# GD32H77x_78x register map
File version: 1.0
CPU: CM7 r1p2, little endian, MPU, FPU, 4 interrupt priority bits
Registers are 32-bit, read-write, reset 0x0 unless marked. A register's access mark holds for its fields unless they carry their own. Offsets are from the block's base; [hi:lo] are bit positions; {n}, {i} and the like mark numbered series.

## NVMC — Non-volatile memory controller
Base 0x52002000
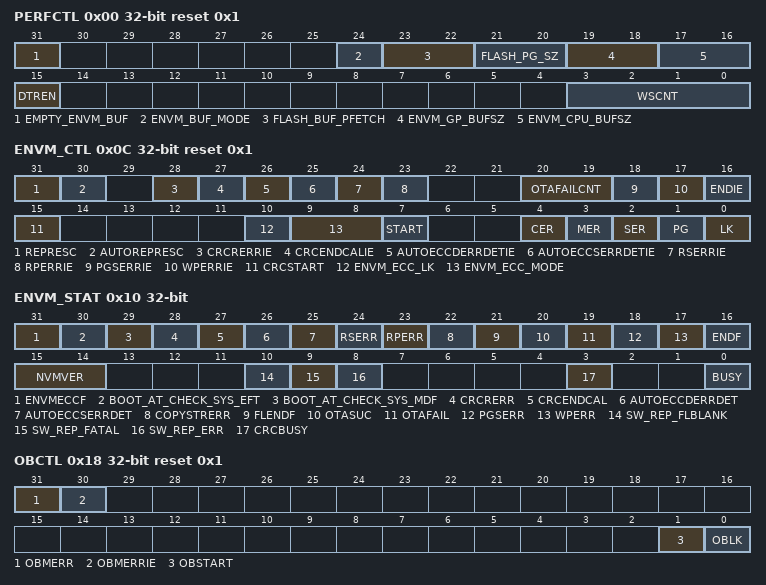
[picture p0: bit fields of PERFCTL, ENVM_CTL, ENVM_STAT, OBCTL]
0x00 PERFCTL access per field reset 0x1 — NVM performance control register
  [31] EMPTY_ENVM_BUF wo — Empty eNVM buffer (general buffer and CPU buffer) function, takes effect when buffer is idle.
  [24] ENVM_BUF_MODE rw — ENVM buffer mode
  [23:22] FLASH_BUF_PFETCH rw — Flash buffer prefetch control.
  [21:20] FLASH_PG_SZ rw — Flash program size.
  [19:18] ENVM_GP_BUFSZ rw — ENVM general purpose buffer size (for masters except CPU).
  [17:16] ENVM_CPU_BUFSZ rw — ENVM CPU buffer size
  [15] DTREN rw — Flash DTR (Double Transfer Rate) mode enable. (Not for case4)
  [3:0] WSCNT rw — Wait state counter register
0x04 ENVM_KEY wo — ENVM unlock key register
  [31:0] KEY — NVMC_ENVM_CTL unlock register
0x08 OBKEY wo — Option byte unlock key register
  [31:0] OBKEY — These bits are only be written by software.
0x0C ENVM_CTL access per field reset 0x1 — ENVM control register
  [31] REPRESC wo — Clear the result of the self-repair function, including the counter, error address, and status. (Including ROBBCNT, ERR2CNT, ERR1CNT, FLBLANK bit in NVMC_ENVM_REPCS register, NVMC_ENVM_ROBBADDRx, NVMC_ENVM_UNREPECCADDRx). The repair function refers to the self-check repair function after the reset.
  [30] AUTOREPRESC wo — Clear the result of the automatic repair function, including the counter, error address, and status. (Including AUTOECCSERRDET, AUTOECCDERRDET bit in NVMC_ENVM_STAT register, NMIERRINT, FLBLANK, ECC1CNTIF, ECC2CNTIF, REPERRSTAT bit in NVMC_ENVM_REPCS register, NVMC_ENVM_AUTOERR1ADDRx, NVMC_ENVM_AUTOERR2ADDRx, NVMC_NMIERRADDR). The automatic repair function refers to the automatic repair function in the process of bus reading eNVM.
  [28] CRCRERRIE rw — ENVM CRC read error interrupt enable
  [27] CRCENDCALIE rw — ENVM CRC end of calculation interrupt enable
  [26] AUTOECCDERRDETIE rw — ENVM ECC two bit errors detect interrupt enable.
  [25] AUTOECCSERRDETIE rw — ENVM ECC one bit error detect interrupt enable.
  [24] RSERRIE rw — Read secure error interrupt enable.
  [23] RPERRIE rw — Read protection error interrupt enable
  [20:19] OTAFAILCNT rw — OTA fail times count, this bit resets upon power-on reset, but is unaffected by system reset.
  [18] PGSERRIE rw — Program sequence error interrupt enable
  [17] WPERRIE rw — Erase / program protection error interrupt enable
  [16] ENDIE rw — End of operation interrupt enable
  [15] CRCSTART rw — CRC check is enabled to check the eNVM content between the NVMC_OBREPSTADDR_MDF and the NVMC_OBREPENDADDR_MDF. When the end or error occurs, this bit is cleared by hardware.
  [10] ENVM_ECC_LK rw — ENVM_ECC_LK, which can only write 1. After writing 1, ENVM_ECC_MODE cannot be overwritten. The ENVM_ECC_MODE is used to test related functions. After the test is complete, users are advised to enable and lock the ENVM_ECC_LK function.
  [9:8] ENVM_ECC_MODE rw — ENVM ECC mode configuration bit
  [7] START rw — Send erase command to NVMC
  [4] CER rw — Chip erase command bit
  [3] MER rw — ENVM mass erase command bit (Not for case4)
  [2] SER rw — ENVM sector erase command bit
  [1] PG rw — ENVM program command bit
  [0] LK rw — NVMC_ENVM_CTL lock bit
0x10 ENVM_STAT access per field — ENVM status register
  [31] ENVMECCF ro — ENVM ECC function flag.
  [30] BOOT_AT_CHECK_SYS_EFT ro — Flag generated by the option byte EFT, indicating boot from the check_bootLoader (Not for case4)
  [29] BOOT_AT_CHECK_SYS_MDF ro — Flag generated by the option byte MDF, indicating boot from the check_bootLoader. This bit contains only the FW_UPDATE and software self-check settings. (Not for case4)
  [28] CRCRERR rw — CRC read error flag
  [27] CRCENDCAL rw — CRC end of calculation flag
  [26] AUTOECCDERRDET ro — Two bit errors detect flag bit.
  [25] AUTOECCSERRDET ro — One bit error detect flag bit.
  [24] RSERR rw — Read secure error flag bit.
  [23] RPERR rw — Read protection error flag bit.
  [22] COPYSTRERR rw — Copy startup failure error flag bit.
  [21] FLENDF rw — End of flash operation flag bit. (Not for case4)
  [20] OTASUC rw — OTA upgrade, check_bootloader check success flag. (Not for case4)
  [19] OTAFAIL rw — OTA upgrade, check_bootloader check failure flag. (Not for case4)
  [18] PGSERR rw — Program sequence error flag bit.
  [17] WPERR rw — Erase / program protection error flag bit.
  [16] ENDF rw — End of operation flag bit.
  [15:14] NVMVER ro — Nvm version
  [10] SW_REP_FLBLANK rw — Software self-check repair flash backup content blank flag (Not for case4)
  [9] SW_REP_FATAL rw — Software self-check repair fatal error flag (Not for case4)
  [8] SW_REP_ERR rw — Software self-check repair error flag (Not for case4)
  [3] CRCBUSY ro — ENVM CRC busy flag bit
  [0] BUSY ro — The eNVM is busy bit
0x14 ENVM_ADDR — ENVM address register
  [31:0] ADDR — ENVM erase command address bits
0x18 OBCTL reset 0x1 — Option byte control register
  [31] OBMERR — Option byte modify error flag.
  [30] OBMERRIE — Option byte modify error interrupt enable.
  [1] OBSTART — Send option byte change command to NVMC bit.
  [0] OBLK — NVMC_OBCTL lock bit
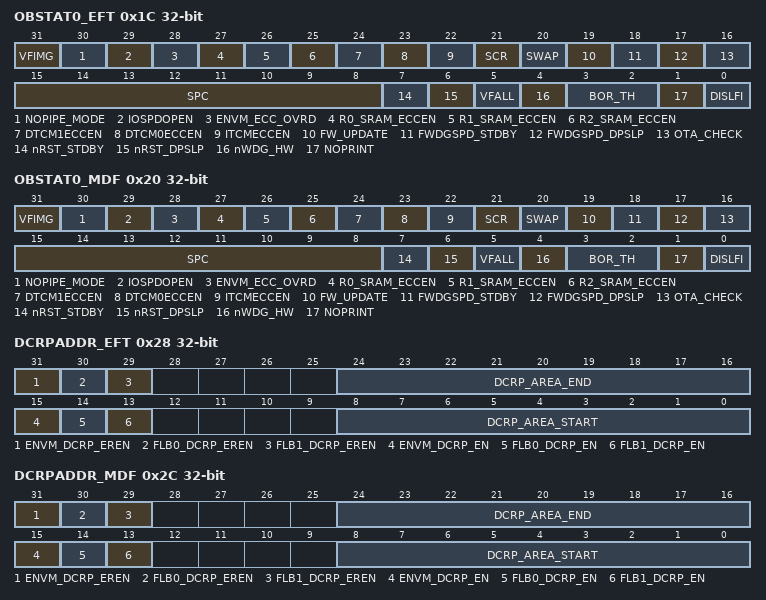
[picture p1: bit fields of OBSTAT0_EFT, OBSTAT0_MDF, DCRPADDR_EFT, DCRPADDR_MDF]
0x1C OBSTAT0_EFT ro — Option byte status register 0
  [31] VFIMG — Firmware image verification enable bit
  [30] NOPIPE_MODE — Pipeline mode
  [29] IOSPDOPEN — Allowed enable status bit for I/O speed optimization at low-voltage.
  [28] ENVM_ECC_OVRD — ENVM ECC override enable status bit
  [27] R0_SRAM_ECCEN — Region 0 SRAM ECC enable status bit
  [26] R1_SRAM_ECCEN — Region 1 SRAM ECC enable status bit
  [25] R2_SRAM_ECCEN — Region 2 SRAM ECC enable status bit
  [24] DTCM1ECCEN — DTCM1 ECC function enable status bit
  [23] DTCM0ECCEN — DTCM0 ECC function enable status bit
  [22] ITCMECCEN — ITCM ECC function enable status bit
  [21] SCR — Secure mode status bit
  [20] SWAP — SWAP status bit (Not for case2 and case4)
  [19] FW_UPDATE — Firmware update status bit (Not for case4)
  [18] FWDGSPD_STDBY — FWDGT suspend option in standby mode status bit
  [17] FWDGSPD_DPSLP — FWDGT suspend option in deepsleep mode status bit
  [16] OTA_CHECK — OTA check status bit (Not for case4)
  [15:8] SPC — Security protection level option byte status bits
  [7] nRST_STDBY — Option byte standby reset status bit
  [6] nRST_DPSLP — Option byte deepsleep reset status bit
  [5] VFALL — Firmware image (image must contain a certificate) verification enable bit
  [4] nWDG_HW — Watchdog status bit
  [3:2] BOR_TH — BOR threshold status bits
  [1] NOPRINT — No information is printed during secure boot
  [0] DISLFI — Licensed firmware install ( LFI ) disable
0x20 OBSTAT0_MDF — Option byte status register 0
  [31] VFIMG — Firmware image verification enable bit
  [30] NOPIPE_MODE — Pipeline mode
  [29] IOSPDOPEN — Allowed enable configuration bit for I/O speed optimization at low-voltage.
  [28] ENVM_ECC_OVRD — ENVM ECC override enable configuration bit
  [27] R0_SRAM_ECCEN — Region 0 SRAM ECC enable configuration bit
  [26] R1_SRAM_ECCEN — Region 1 SRAM ECC enable configuration bit
  [25] R2_SRAM_ECCEN — Region 2 SRAM ECC enable configuration bit
  [24] DTCM1ECCEN — DTCM1 ECC function enable configuration bit
  [23] DTCM0ECCEN — DTCM0 ECC function enable configuration bit
  [22] ITCMECCEN — ITCM ECC function enable configuration bit
  [21] SCR — Secure mode configuration bit
  [20] SWAP — SWAP configuration bit (Not for case2 and case4)
  [19] FW_UPDATE — Firmware update configuration bit (Not for case4)
  [18] FWDGSPD_STDBY — FWDGT suspend option in standby mode configuration bit
  [17] FWDGSPD_DPSLP — FWDGT suspend option in deepsleep mode configuration bit
  [16] OTA_CHECK — OTA check configuration bits (Not for case4)
  [15:8] SPC — Security protection level option configuration bits
  [7] nRST_STDBY — Option byte standby reset configuration bit
  [6] nRST_DPSLP — Option byte deepsleep reset configuration bit
  [5] VFALL — Firmware image (image must contain a certificate) verification configuration bit
  [4] nWDG_HW — Watchdog configuration bit
  [3:2] BOR_TH — BOR threshold configuration bits
  [1] NOPRINT — No information is printed during secure boot
  [0] DISLFI — Licensed firmware install ( LFI ) disable
0x28 DCRPADDR_EFT ro — DCRP address register
  [31] ENVM_DCRP_EREN — ENVM DCRP area erase enable status bit.
  [30] FLB0_DCRP_EREN — Flash bank0 DCRP area erase enable status bit.
  [29] FLB1_DCRP_EREN — Flash bank1 DCRP area erase enable status bit.
  [24:16] DCRP_AREA_END — DCRP area end address status bits
  [15] ENVM_DCRP_EN — ENVM region DCRP function enable status bits
  [14] FLB0_DCRP_EN — Flash bank0 region DCRP function enable status bits
  [13] FLB1_DCRP_EN — Flash bank1 region DCRP function enable status bits
  [8:0] DCRP_AREA_START — DCRP area start address status bits
0x2C DCRPADDR_MDF — DCRP address register
  [31] ENVM_DCRP_EREN — ENVM DCRP area erase enable configuration bit. (Case4: This bit defaults to 1 and cannot be modified)
  [30] FLB0_DCRP_EREN — Flash bank0 DCRP area erase enable configuration bit. (Not for case4)
  [29] FLB1_DCRP_EREN — Flash bank1 DCRP area erase enable configuration bit. (Not for case4)
  [24:16] DCRP_AREA_END — DCRP area end address configuration bits
  [15] ENVM_DCRP_EN — ENVM region DCRP function enable configuration bits (Case4: This bit defaults to 1 and cannot be modified)
  [14] FLB0_DCRP_EN — Flash bank0 region DCRP function enable configuration bits (Not for case4)
  [13] FLB1_DCRP_EN — Flash bank1 region DCRP function enable configuration bits (Not for case4)
  [8:0] DCRP_AREA_START — DCRP area start address configuration bits
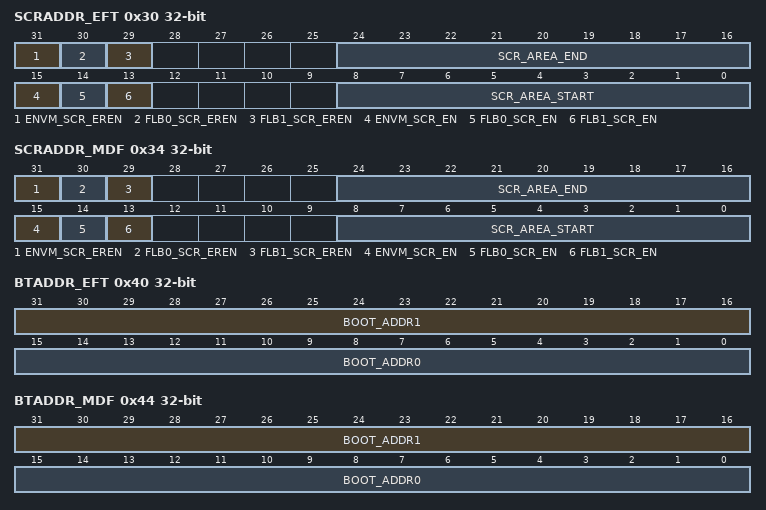
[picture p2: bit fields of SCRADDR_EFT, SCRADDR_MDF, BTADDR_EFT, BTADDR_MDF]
0x30 SCRADDR_EFT ro — Secure address register
  [31] ENVM_SCR_EREN — ENVM secure user area erase enable option status bit.
  [30] FLB0_SCR_EREN — Flash bank0 secure user area erase enable option status bit.
  [29] FLB1_SCR_EREN — Flash bank1 secure user area erase enable option status bit.
  [24:16] SCR_AREA_END — Secure user area end address status bits
  [15] ENVM_SCR_EN — ENVM region SCR function enable status bits
  [14] FLB0_SCR_EN — Flash bank0 region SCR function enable status bits
  [13] FLB1_SCR_EN — Flash bank1 region SCR function enable status bits
  [8:0] SCR_AREA_START — Secure user area start address status bits
0x34 SCRADDR_MDF — Secure address register
  [31] ENVM_SCR_EREN — ENVM secure user area erase enable option configuration bit. (Case4: This bit defaults to 1 and cannot be modified)
  [30] FLB0_SCR_EREN — Flash bank0 secure user area erase enable option configuration bit. (Not for case4)
  [29] FLB1_SCR_EREN — Flash bank1 secure user area erase enable option configuration bit. (Not for case4)
  [24:16] SCR_AREA_END — Secure user area end address configuration bits
  [15] ENVM_SCR_EN — ENVM region SCR function enable configuration bits (Case4: This bit defaults to 1 and cannot be modified)
  [14] FLB0_SCR_EN — Flash bank0 region SCR function enable configuration bits (Not for case4)
  [13] FLB1_SCR_EN — Flash bank1 region SCR function enable configuration bits (Not for case4)
  [8:0] SCR_AREA_START — Secure user area start address configuration bits
0x38 WP_ENVM_EFT ro reset 0xFFFF — NVMC erase / program protection register of ENVM
  [15:0] WP — ENVM sector erase / program protection option status bit
0x3C WP_ENVM_MDF — NVMC erase / program protection register of ENVM
  [15:0] WP — ENVM sector erase / program protection option configuration bit
0x40 BTADDR_EFT ro — Boot address register
  [31:16] BOOT_ADDR1 — Boot address 1 status bits
  [15:0] BOOT_ADDR0 — Boot address 0 status bits
0x44 BTADDR_MDF — Boot address register
  [31:16] BOOT_ADDR1 — Boot address 1 configuration bits.
  [15:0] BOOT_ADDR0 — Boot address 0 configuration bits.
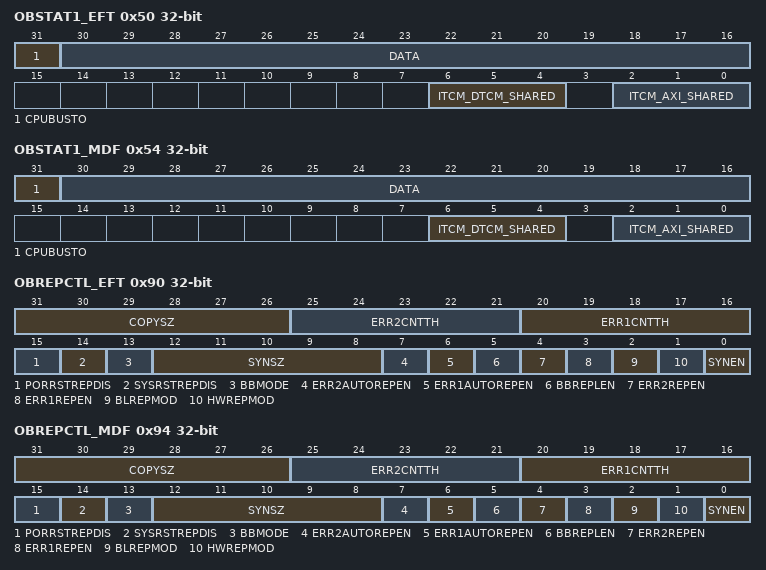
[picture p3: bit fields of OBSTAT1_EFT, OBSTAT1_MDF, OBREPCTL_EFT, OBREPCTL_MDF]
0x50 OBSTAT1_EFT ro — Option byte status register 1
  [31] CPUBUSTO — CPU bus timeout enable bit.
  [30:16] DATA — User defined option byte data status value
  [6:4] ITCM_DTCM_SHARED — ITCM and DTCM RAM sharing status bit
  [2:0] ITCM_AXI_SHARED — ITCM and AXI RAM sharing status bit
0x54 OBSTAT1_MDF — Option byte status register 1
  [31] CPUBUSTO — CPU bus timeout enable bit.
  [30:16] DATA — User defined option byte data configuration value
  [6:4] ITCM_DTCM_SHARED — ITCM and DTCM RAM sharing configuration configure bit.
  [2:0] ITCM_AXI_SHARED — ITCM and AXI RAM sharing configuration bits.
0x5C ENVM_CRCRESULT ro
  [31:0] CRC_RESULT — CRC calculation result, if CRCRERR is set 1, the value of CRC_RESULT[31:0] is 0x0000 0000.
0x60 ENVM_SW_REP_FATAL_ADDR ro — ENVM software repair fatal address register
  [31:0] SW_REP_FATAL_ADDR — The first blank address of the flash backup area or fatal address detected by software self-check. The address is in eNVM address area.
0x80 WP0_FLASH_EFT ro — NVMC erase / program protection register 0 of flash
  [31:0] WP — Flash sector erase / program protection option status bit
0x84 WP1_FLASH_EFT ro — NVMC erase / program protection register 1 of flash
  [27:0] WP — Flash sector erase / program protection option status bit
0x88 WP0_FLASH_MDF — NVMC erase / program protection register 0 of flash
  [31:0] WP — Flash sector erase / program protection option configuration bits.
0x8C WP1_FLASH_MDF — NVMC erase / program protection register 1 of flash
  [27:0] WP — Flash sector erase / program protection option configuration bits.
0x90 OBREPCTL_EFT ro — Option byte repair control register
  [31:26] COPYSZ — Copy size during OTA upgrade, the granularity is 32KB, that is, when 6'h3F is set, 2MB of space is copy zone.
  [25:21] ERR2CNTTH — Two bit error counter threshold status bit
  [20:16] ERR1CNTTH — One bit error counter threshold status bit
  [15] PORRSTREPDIS — The power-on reset self-check repair function enable status bit
  [14] SYSRSTREPDIS — The system reset self-check repair function enable status bit
  [13] BBMODE — Mode of determining whether the repair is successful after the repair.
  [12:8] SYNSZ — Synchronize size status bit
  [7] ERR2AUTOREPEN — 2 bit error automatic repair enable status bit
  [6] ERR1AUTOREPEN — 1 bit error automatic repair enable status bit
  [5] BBREPLEN — Bad block address replace status bit
  [4] ERR2REPEN — Enable two bit error repair in self-repair function status bit
  [3] ERR1REPEN — Enable one bit error repair in self-repair function status bit
  [2] BLREPMOD — Check_bootloader self-check mode status bit
  [1] HWREPMOD — Hardware self-check mode status bit
  [0] SYNEN — The synchronization mode enable status bit
0x94 OBREPCTL_MDF — Option byte repair control register
  [31:26] COPYSZ — Copy size during OTA upgrade, the granularity is 32KB, that is, when 6'h3F is set, 2MB of space is copy zone.
  [25:21] ERR2CNTTH — Two bit error counter threshold configure bit
  [20:16] ERR1CNTTH — One bit error counter threshold configure bit
  [15] PORRSTREPDIS — The power-on reset self-check repair function enable configure bit
  [14] SYSRSTREPDIS — The system reset self-check repair function enable configure bit
  [13] BBMODE — Mode of determining whether the repair is successful after the repair.
  [12:8] SYNSZ — Synchronize size configure bit
  [7] ERR2AUTOREPEN — 2 bit error automatic repair enable configure bit
  [6] ERR1AUTOREPEN — 1 bit error automatic repair enable configure bit
  [5] BBREPLEN — Bad block address replace configure bit
  [4] ERR2REPEN — Enable two bit error repair in self-repair function configure bit
  [3] ERR1REPEN — Enable one bit error repair in self-repair function configure bit
  [2] BLREPMOD — Check_bootloader self-check mode configure bit
  [1] HWREPMOD — Hardware self-check mode configure bit
  [0] SYNEN — The synchronization mode enable configure bit
0x98 OBREPSTADDR_EFT ro reset 0x8000000 — Option byte repair start address register
  [20:5] STARTADDR — Self-check repair start offset address status bit
0x9C OBREPENDADDR_EFT ro reset 0x8000000 — Option byte repair end address register
  [20:5] ENDADDR — Self-check repair end offset address status bit
0xA0 OBREPSTADDR_MDF reset 0x8000000 — Option byte repair start address register
  [20:5] STARTADDR — Self-check repair start offset address configuration bits.
0xA4 OBREPENDADDR_MDF reset 0x8000000 — Option byte repair end address register
  [20:5] ENDADDR — Self-check repair end offset address configuration bits.
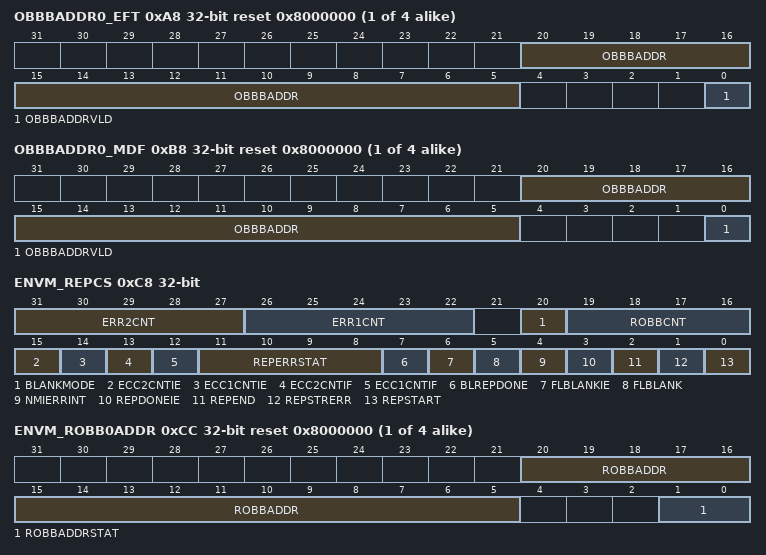
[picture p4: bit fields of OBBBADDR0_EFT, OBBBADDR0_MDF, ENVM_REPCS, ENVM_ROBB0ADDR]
{0xA8+4i} OBBBADDR{i}_EFT ro reset 0x8000000 (i=0..3) — Option byte bad block address register {i}
  [20:5] OBBBADDR — Bad block address status bit
  [0] OBBBADDRVLD — The bad block address recorded by the option byte valid status bit
{0xB8+4i} OBBBADDR{i}_MDF reset 0x8000000 (i=0..3) — Option byte bad block address register {i}
  [20:5] OBBBADDR — Bad block address configure bit
  [0] OBBBADDRVLD — The bad block address recorded by the option byte valid configure bit
0xC8 ENVM_REPCS — ENVM repair function control and status register
  [31:27] ERR2CNT — During the self-check, the number of 2 bit error occurrences without repair.
  [26:22] ERR1CNT — During the self-check, the number of 1 bit error occurrences without repair.
  [20] BLANKMODE — Flash backup content blank mode
  [19:16] ROBBCNT — Bad block count bit
  [15] ECC2CNTIE — The number of 2 bit errors is greater than or equal to the threshold interrupt enable, the threshold value is determined by ERR2CNTTH[4:0].
  [14] ECC1CNTIE — The number of 1 bit error is greater than or equal to the threshold Interrupt enable, the threshold value is determined by ERR1CNTTH[4:0].
  [13] ECC2CNTIF — Flag generated when the number of 2 bit errors is greater than or equal to the threshold, the threshold value is determined by ERR2CNTTH[4:0].
  [12] ECC1CNTIF — Flag generated when the number of 1 bit error is greater than or equal to the threshold, the threshold value is determined by ERR1CNTTH[4:0].
  [11:8] REPERRSTAT — Self-check result, error status.
  [7] BLREPDONE — Check_bootloader writes the register to release the CPU after the check_bootloader self-check is done. (Success or failure can be written)
  [6] FLBLANKIE — The flash backup content blank interruption was enabled
  [5] FLBLANK — Flash backup content is blank flag
  [4] NMIERRINT — AXI read, repair failure with 3-bit error.
  [3] REPDONEIE — Self-repair done interrupt enable
  [2] REPEND — Self-repair end flag.
  [1] REPSTRERR — Self-check repair configuration error bit
  [0] REPSTART — Repair start bit
{0xCC+4i} ENVM_ROBB{i}ADDR reset 0x8000000 (i=0..3) — ENVM read only bad block address register {i}
  [20:5] ROBBADDR — During the self-check process, the register records the bad block address, which only records the address that still has the error after repair. The address is in eNVM address area, the granularity is 256bit.
  [1:0] ROBBADDRSTAT — State of ROBBADDR[15:0]
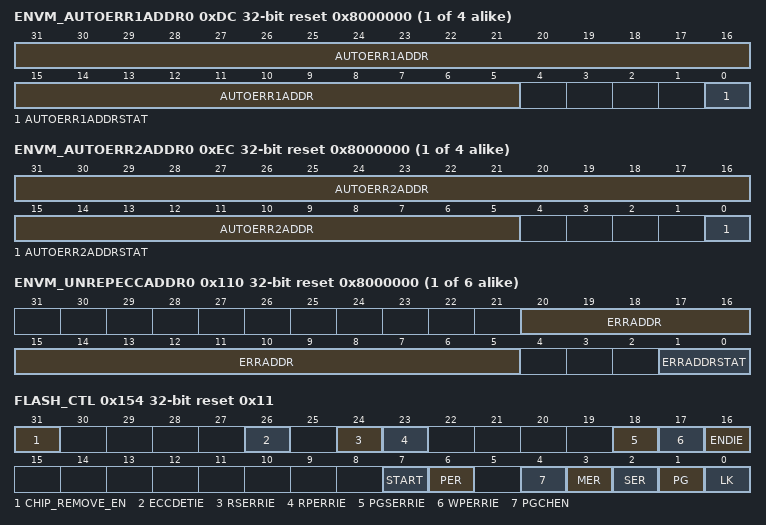
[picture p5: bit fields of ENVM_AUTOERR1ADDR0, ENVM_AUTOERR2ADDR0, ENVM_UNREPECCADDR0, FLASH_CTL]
{0xDC+4i} ENVM_AUTOERR1ADDR{i} reset 0x8000000 (i=0..3) — ENVM automatic repair ECC 1 bit error address register {i}
  [31:5] AUTOERR1ADDR — The address where 1 bit error occurs when the bus reads eNVM. Recorded cases include error that does not repair and 1 bit error remained after auto repair. The address is in eNVM address area, the granularity is 256bit.
  [0] AUTOERR1ADDRSTAT — State of AUTOERR1ADDR[26:0]
{0xEC+4i} ENVM_AUTOERR2ADDR{i} reset 0x8000000 (i=0..3) — ENVM automatic repair ECC 2 bit error address register {i}
  [31:5] AUTOERR2ADDR — The address where 2 bit error occurs when the bus reads eNVM. Recorded cases include error that does not repair and 2 bit error remained after auto repair. The address is in eNVM address area, the granularity is 256bit.
  [0] AUTOERR2ADDRSTAT — State of AUTOERR2ADDR[26:0]
0xFC BLANKADDR reset 0x8000000 — Blank address register
  [20:5] BLANKADDR — Flash backup blank corresponding address. The address is in eNVM address area, the granularity is 256bit. This bit field records only the last address that appears.
0x100 PID0 ro — Product ID register 0
  [31:0] PID — Product reserved ID code register x
0x104 PID1 ro — Product ID register 1
  [31:0] PID — Product reserved ID code register x
0x108 NMIERRADDR reset 0x8000000 — Not maskable interrupt error address register
  [20:5] NMIERRADDR — AXI read with uncorrectable error interrupt (including case of failure to repair with 3-bit error). The address is in eNVM address area, the granularity is 256bit.
{0x110+4i} ENVM_UNREPECCADDR{i} reset 0x8000000 (i=0..5) — ENVM self-check unrepaired ECC error address register {i}
  [20:5] ERRADDR — During the self-check process, records the 1/2 bit error address that occurs if it is not repaired. The address is in eNVM address area, the granularity is 256bit.
  [1:0] ERRADDRSTAT — State of ERRADDR[15:0]
0x128 ENVM_OTAFAILADDR reset 0x8000000 — ENVM OTA fail address register
  [20:0] OTAFAILADDR — Record the address of the last OTA check failure
0x150 FLASH_KEY wo — FLASH unlock key register
  [31:0] KEY — NVMC_FLASH_CTL unlock register
0x154 FLASH_CTL reset 0x11 — FLASH control register
  [31] CHIP_REMOVE_EN — Protection-removed chip erase enable
  [26] ECCDETIE — Flash ECC two bit errors detect interrupt enable.
  [24] RSERRIE — Read secure error interrupt enable.
  [23] RPERRIE — Read protection error interrupt enable
  [18] PGSERRIE — Program sequence error interrupt enable
  [17] WPERRIE — Erase / program protection error interrupt enable
  [16] ENDIE — End of operation interrupt enable
  [7] START — Send erase command to NVMC
  [6] PER — Page erase command bit
  [4] PGCHEN — Check flash programming area enable
  [3] MER — Mass erase command bit
  [2] SER — Sector erase command bit
  [1] PG — Main Flash program command bit
  [0] LK — NVMC_FLASH_CTL lock bit
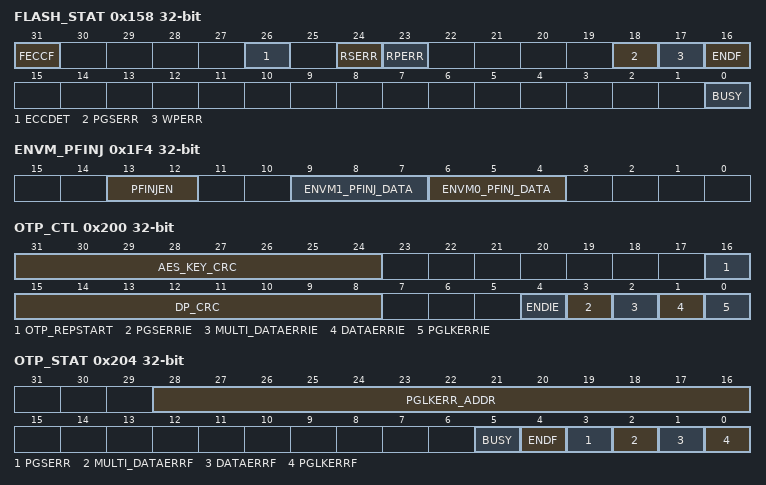
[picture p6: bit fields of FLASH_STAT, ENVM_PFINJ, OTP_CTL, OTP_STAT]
0x158 FLASH_STAT access per field — FLASH status register
  [31] FECCF ro — Flash ECC function flag.
  [26] ECCDET rw — Two bit errors detect flag.
  [24] RSERR rw — Read secure error flag bit.
  [23] RPERR rw — Read protection error flag bit.
  [18] PGSERR rw — Program sequence error flag bit.
  [17] WPERR rw — Erase / program protection error flag bit.
  [16] ENDF rw — End of operation flag bit.
  [0] BUSY ro — The Flash is busy bit
0x15C FLASH_ADDR — FLASH address register
  [31:0] ADDR — Flash erase command address bits
0x160 FLASH_ECCADDR ro — Flash ECC error address register
  [31:0] ECCADDR — Address of byte where an ECC error is detected
0x1F0 ENVM_PFINJ_KEY wo — ENVM program fault inject unlock key register
  [31:0] PFINJ_KEY — NVMC_ENVM_PFINJ unlock register
0x1F4 ENVM_PFINJ — ENVM program fault inject register
  [13:12] PFINJEN — Program fault inject enable
  [9:7] ENVM1_PFINJ_DATA — When PFINJEN[1:0] is set to 0x3, ENVM1_PFINJ_DATA[*] is set 1, the corresponding position of ENVM1_DATAIN[*] is reversed.
  [6:4] ENVM0_PFINJ_DATA — When PFINJEN[1:0] is set to 0x3, ENVM0_PFINJ_DATA[*] is set 1, the corresponding position of ENVM0_DATAIN[*] is reversed.
0x200 OTP_CTL access per field — OTP control register
  [31:24] AES_KEY_CRC ro — 8-bits CRC calculation result value of AES key bits
  [16] OTP_REPSTART rw — OTP repair start signal
  [15:8] DP_CRC ro — 8-bits CRC calculation result value of debug password data
  [4] ENDIE rw — The OTP operation end interrupt enable
  [3] PGSERRIE rw — OTP program sequence error interrupt enable
  [2] MULTI_DATAERRIE rw — Multi-redundant data error interrupt enable
  [1] DATAERRIE rw — Data error interrupt enable
  [0] PGLKERRIE rw — Program at lock state error interrupt enable
0x204 OTP_STAT access per field — OTP status register
  [28:16] PGLKERR_ADDR ro — When PGLKERRF is set 1, this bit records the lower 13 bits of the logical address corresponding to the error. PGLKERR_ADDR[12:0] is updated when a new error occurs.
  [5] BUSY ro — The OTP is busy bit
  [4] ENDF rw — End of operation flag bit.
  [3] PGSERR rw — OTP program sequence error flag bit.
  [2] MULTI_DATAERRF rw — Multi-redundant data error flag
  [1] DATAERRF rw — Redundant data error flag
  [0] PGLKERRF rw — Program at lock state error flag
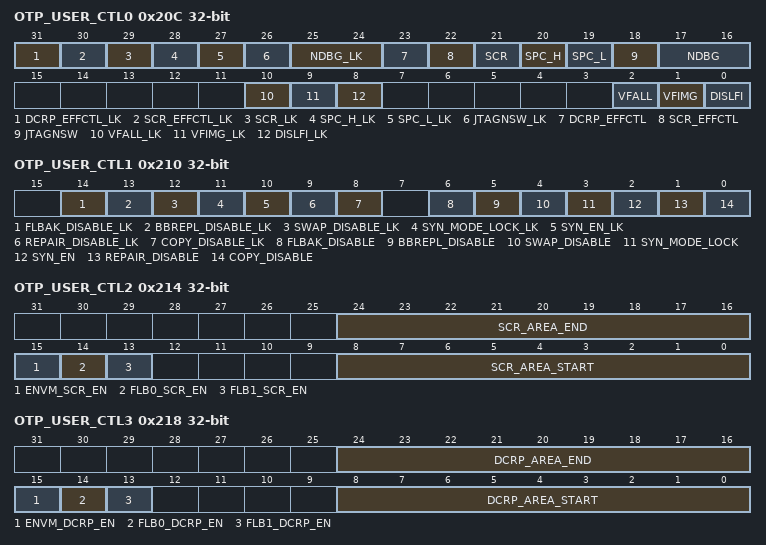
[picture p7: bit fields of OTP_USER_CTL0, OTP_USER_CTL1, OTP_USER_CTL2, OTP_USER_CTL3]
0x20C OTP_USER_CTL0 ro — OTP user control register 0
  [31] DCRP_EFFCTL_LK — DCRP_EFFCTL lock bit
  [30] SCR_EFFCTL_LK — SCR_EFFCTL lock bit
  [29] SCR_LK — SCR lock bit
  [28] SPC_H_LK — SPC_H lock bit
  [27] SPC_L_LK — SPC_L lock bit
  [26] JTAGNSW_LK — JTAGNSW lock bit
  [25:24] NDBG_LK — NDBG lock bit
  [23] DCRP_EFFCTL — DCRP area effective control bit
  [22] SCR_EFFCTL — SCR area effective control bit
  [21] SCR — Secure mode enable
  [20] SPC_H — Configure security protection to level high
  [19] SPC_L — Configure security protection to level low
  [18] JTAGNSW — SW or JTAG debugger select
  [17:16] NDBG — Debugging permission setting
  [10] VFALL_LK — VFALL lock bit
  [9] VFIMG_LK — VFIMG lock bit
  [8] DISLFI_LK — DISLFI lock bit
  [2] VFALL — Firmware image (Image must contain a certificate) verification enable bit
  [1] VFIMG — Firmware image verification enable bit
  [0] DISLFI — Licensed firmware install (LFI) disable
0x210 OTP_USER_CTL1 ro — OTP user control register 1
  [14] FLBAK_DISABLE_LK — FLBAK_DISABLE lock bit
  [13] BBREPL_DISABLE_LK — BBREPL_DISABLE lock bit
  [12] SWAP_DISABLE_LK — SWAP_DISABLE lock bit
  [11] SYN_MODE_LOCK_LK — SYN_MODE_LOCK lock bit
  [10] SYN_EN_LK — SYN_EN lock bit
  [9] REPAIR_DISABLE_LK — REPAIR_DISABLE lock bit
  [8] COPY_DISABLE_LK — COPY_DISABLE lock bit
  [6] FLBAK_DISABLE — Disable the flash backup function.
  [5] BBREPL_DISABLE — Force disable the bad block replacement function.
  [4] SWAP_DISABLE — Disable the backup area swap function.
  [3] SYN_MODE_LOCK — Lock the current synchronization mode configuration.
  [2] SYN_EN — Force enable the synchronization mode.
  [1] REPAIR_DISABLE — Disable self-check and repair function.
  [0] COPY_DISABLE — Disable OTA upgrade copy function.
0x214 OTP_USER_CTL2 ro — OTP user control register 2
  [24:16] SCR_AREA_END — Secure user area end address bits
  [15] ENVM_SCR_EN — ENVM region SCR function enable configuration bits
  [14] FLB0_SCR_EN — Flash bank0 region SCR function enable configuration bits
  [13] FLB1_SCR_EN — Flash bank1 region SCR function enable configuration bits
  [8:0] SCR_AREA_START — Secure user area start address bits
0x218 OTP_USER_CTL3 ro — OTP user control register 3
  [24:16] DCRP_AREA_END — DCRP area end address bits
  [15] ENVM_DCRP_EN — ENVM region DCRP function enable status bits
  [14] FLB0_DCRP_EN — Flash bank0 region DCRP function enable status bits
  [13] FLB1_DCRP_EN — Flash bank1 region DCRP function enable status bits
  [8:0] DCRP_AREA_START — DCRP area start address bits
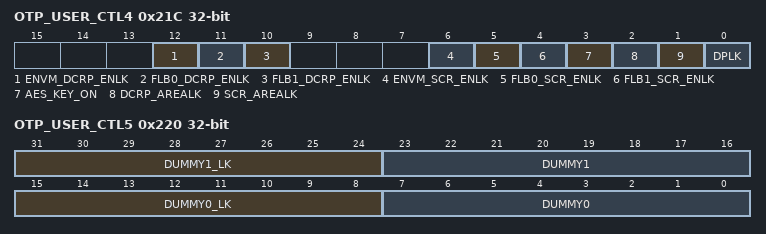
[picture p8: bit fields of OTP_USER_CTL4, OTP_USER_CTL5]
0x21C OTP_USER_CTL4 ro — OTP user control register 4
  [12] ENVM_DCRP_ENLK — ENVM_DCRP_EN of NVMC_OTP_USER_CTL3 register lock bit
  [11] FLB0_DCRP_ENLK — FLB0_DCRP_EN of NVMC_OTP_USER_CTL3 register lock bit
  [10] FLB1_DCRP_ENLK — FLB1_DCRP_EN of NVMC_OTP_USER_CTL3 register lock bit
  [6] ENVM_SCR_ENLK — ENVM_SCR_EN of NVMC_OTP_USER_CTL2 register lock bit
  [5] FLB0_SCR_ENLK — FLB0_SCR_EN of NVMC_OTP_USER_CTL2 register lock bit
  [4] FLB1_SCR_ENLK — FLB1_SCR_EN of NVMC_OTP_USER_CTL2 register lock bit
  [3] AES_KEY_ON — OTP_AES_KEY lock bit
  [2] DCRP_AREALK — DCRP area address lock bit
  [1] SCR_AREALK — Secure user area address lock bit
  [0] DPLK — DBGPSWD_DATA lock bit.
0x220 OTP_USER_CTL5 ro — OTP user control register 5
  [31:24] DUMMY1_LK — DUMMY1[7:0] lock bit
  [23:16] DUMMY1 — Reserve space for other operations
  [15:8] DUMMY0_LK — DUMMY0[7:0] lock bit
  [7:0] DUMMY0 — Reserve space for other operations
0x330 CS ro — NVMC control and status register
  [31] EEBBUSY — Empty eNVM buffer busy bit
